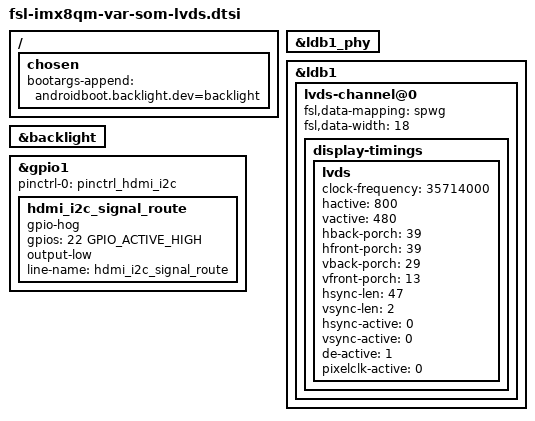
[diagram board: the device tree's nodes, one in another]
/*
 * Copyright 2019 Variscite Ltd.
 *
 * This program is free software; you can redistribute it and/or
 * modify it under the terms of the GNU General Public License
 * as published by the Free Software Foundation; either version 2
 * of the License, or (at your option) any later version.
 *
 * This program is distributed in the hope that it will be useful,
 * but WITHOUT ANY WARRANTY; without even the implied warranty of
 * MERCHANTABILITY or FITNESS FOR A PARTICULAR PURPOSE.  See the
 * GNU General Public License for more details.
 */

/ {
	chosen {
		bootargs-append = "androidboot.backlight.dev=backlight";
	};
};

&ldb1_phy {
	status = "okay";
};

&ldb1 {
	status = "okay";

	lvds-channel@0 {
		fsl,data-mapping = "spwg";
		fsl,data-width = <18>;
		status = "okay";

		display-timings {
			lvds {
				clock-frequency = <35714000>;
				hactive = <800>;
				vactive = <480>;
				hback-porch = <39>;
				hfront-porch = <39>;
				vback-porch = <29>;
				vfront-porch = <13>;
				hsync-len = <47>;
				vsync-len = <2>;
				hsync-active = <0>;
				vsync-active = <0>;
				de-active = <1>;
				pixelclk-active = <0>;
			};
		};
	};
};

&backlight {
	status = "okay";
};

&gpio1 {
	pinctrl-names = "default";
	pinctrl-0 = <&pinctrl_hdmi_i2c>;

	hdmi_i2c_signal_route {
		gpio-hog;
		gpios = <22 GPIO_ACTIVE_HIGH>;
		output-low;
		line-name = "hdmi_i2c_signal_route";
	};
};
